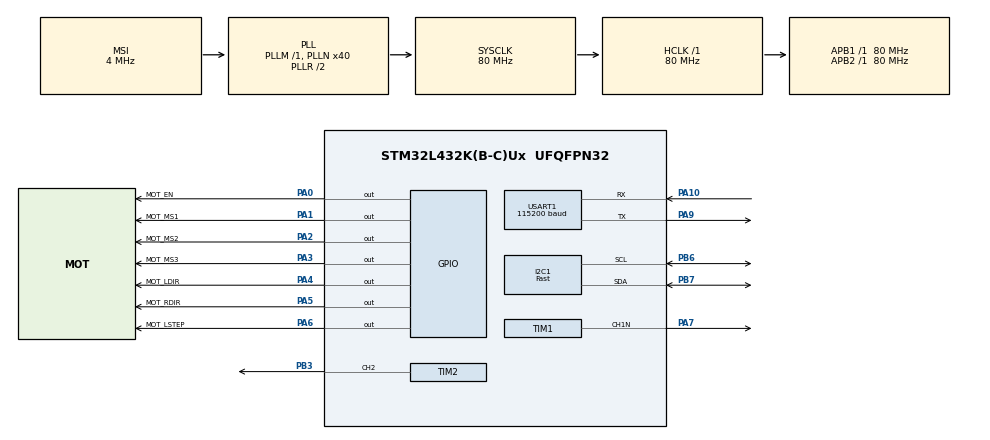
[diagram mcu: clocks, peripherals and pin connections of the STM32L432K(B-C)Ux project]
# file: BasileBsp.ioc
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I2C1.I2C_Speed_Mode=I2C_Fast
I2C1.Timing=0x00702991
Mcu.Family=STM32L4
Mcu.Name=STM32L432K(B-C)Ux
Mcu.Package=UFQFPN32
NVIC.PriorityGroup=NVIC_PRIORITYGROUP_4
NVIC.TIM1_UP_TIM16_IRQn=true\:0\:0\:false\:false\:true\:true
PA0.GPIO_Label=MOT_EN
PA0.GPIO_Speed=GPIO_SPEED_FREQ_VERY_HIGH
PA0.PinState=GPIO_PIN_SET
PA0.Signal=GPIO_Output
PA1.GPIO_Label=MOT_MS1
PA1.GPIO_ModeDefaultOutputPP=GPIO_MODE_OUTPUT_PP
PA1.GPIO_Speed=GPIO_SPEED_FREQ_VERY_HIGH
PA1.PinState=GPIO_PIN_RESET
PA1.Signal=GPIO_Output
PA10.Mode=Asynchronous
PA10.Signal=USART1_RX
PA13\ (JTMS-SWDIO).Mode=Serial_Wire
PA13\ (JTMS-SWDIO).Signal=SYS_JTMS-SWDIO
PA14\ (JTCK-SWCLK).Mode=Serial_Wire
PA14\ (JTCK-SWCLK).Signal=SYS_JTCK-SWCLK
PA2.GPIO_Label=MOT_MS2
PA2.GPIO_ModeDefaultOutputPP=GPIO_MODE_OUTPUT_PP
PA2.GPIO_Speed=GPIO_SPEED_FREQ_VERY_HIGH
PA2.PinState=GPIO_PIN_RESET
PA2.Signal=GPIO_Output
PA3.GPIO_Label=MOT_MS3
PA3.GPIO_ModeDefaultOutputPP=GPIO_MODE_OUTPUT_PP
PA3.GPIO_Speed=GPIO_SPEED_FREQ_VERY_HIGH
PA3.PinState=GPIO_PIN_RESET
PA3.Signal=GPIO_Output
PA4.GPIO_Label=MOT_LDIR
PA4.GPIO_Speed=GPIO_SPEED_FREQ_VERY_HIGH
PA4.Signal=GPIO_Output
PA5.GPIO_Label=MOT_RDIR
PA5.GPIO_Speed=GPIO_SPEED_FREQ_VERY_HIGH
PA5.Signal=GPIO_Output
PA6.GPIO_Label=MOT_LSTEP
PA6.GPIO_Speed=GPIO_SPEED_FREQ_VERY_HIGH
PA6.Signal=GPIO_Output
PA7.Mode=PWM Generation1 CH1N
PA7.Signal=TIM1_CH1N
PA9.Mode=Asynchronous
PA9.Signal=USART1_TX
PB3\ (JTDO-TRACESWO).GPIO_Speed=GPIO_SPEED_FREQ_VERY_HIGH
PB3\ (JTDO-TRACESWO).Signal=S_TIM2_CH2
PB6.Mode=I2C
PB6.Signal=I2C1_SCL
PB7.Mode=I2C
PB7.Signal=I2C1_SDA
ProjectManager.HeapSize=0x200
ProjectManager.StackSize=0x400
ProjectManager.TargetToolchain=Makefile
RCC.AHBFreq_Value=80000000
RCC.APB1Freq_Value=80000000
RCC.APB1TimFreq_Value=80000000
RCC.APB2Freq_Value=80000000
RCC.APB2TimFreq_Value=80000000
RCC.CortexFreq_Value=80000000
RCC.HCLKFreq_Value=80000000
RCC.HSE_VALUE=8000000
RCC.HSI48_VALUE=48000000
RCC.HSI_VALUE=16000000
RCC.LSE_VALUE=32768
RCC.MSI_VALUE=4000000
RCC.PLLN=40
RCC.SYSCLKFreq_VALUE=80000000
RCC.SYSCLKSource=RCC_SYSCLKSOURCE_PLLCLK
RCC.VCOOutputFreq_Value=160000000
SH.S_TIM2_CH2.0=TIM2_CH2,PWM Generation2 CH2
TIM1.AutoReloadPreload=TIM_AUTORELOAD_PRELOAD_ENABLE
TIM1.Channel-PWM\ Generation1\ CH1N=TIM_CHANNEL_1
TIM1.Period=2000
TIM1.Prescaler=80
TIM1.Pulse-PWM\ Generation1\ CH1N=1000
TIM2.AutoReloadPreload=TIM_AUTORELOAD_PRELOAD_ENABLE
TIM2.Channel-PWM\ Generation2\ CH2=TIM_CHANNEL_2
TIM2.ClockDivision=TIM_CLOCKDIVISION_DIV1
TIM2.Period=2000
TIM2.Prescaler=40000
TIM2.Pulse-PWM\ Generation2\ CH2=100
USART1.BaudRate=115200
USART1.VirtualMode-Asynchronous=VM_ASYNC
USART1.WordLength=WORDLENGTH_8B
VP_TIM1_VS_ClockSourceINT.Mode=Internal
VP_TIM2_VS_ClockSourceINT.Mode=Internal
board=BasileBsp

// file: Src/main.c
/**
  ******************************************************************************
  * File Name          : main.c
  * Description        : Main program body
  ******************************************************************************
  ** This notice applies to any and all portions of this file
  * that are not between comment pairs USER CODE BEGIN and
  * USER CODE END. Other portions of this file, whether
  * inserted by the user or by software development tools
  * are owned by their respective copyright owners.
  *
  * COPYRIGHT(c) 2017 STMicroelectronics
  *
  * Redistribution and use in source and binary forms, with or without modification,
  * are permitted provided that the following conditions are met:
  *   1. Redistributions of source code must retain the above copyright notice,
  *      this list of conditions and the following disclaimer.
  *   2. Redistributions in binary form must reproduce the above copyright notice,
  *      this list of conditions and the following disclaimer in the documentation
  *      and/or other materials provided with the distribution.
  *   3. Neither the name of STMicroelectronics nor the names of its contributors
  *      may be used to endorse or promote products derived from this software
  *      without specific prior written permission.
  *
  * THIS SOFTWARE IS PROVIDED BY THE COPYRIGHT HOLDERS AND CONTRIBUTORS "AS IS"
  * AND ANY EXPRESS OR IMPLIED WARRANTIES, INCLUDING, BUT NOT LIMITED TO, THE
  * IMPLIED WARRANTIES OF MERCHANTABILITY AND FITNESS FOR A PARTICULAR PURPOSE ARE
  * DISCLAIMED. IN NO EVENT SHALL THE COPYRIGHT HOLDER OR CONTRIBUTORS BE LIABLE
  * FOR ANY DIRECT, INDIRECT, INCIDENTAL, SPECIAL, EXEMPLARY, OR CONSEQUENTIAL
  * DAMAGES (INCLUDING, BUT NOT LIMITED TO, PROCUREMENT OF SUBSTITUTE GOODS OR
  * SERVICES; LOSS OF USE, DATA, OR PROFITS; OR BUSINESS INTERRUPTION) HOWEVER
  * CAUSED AND ON ANY THEORY OF LIABILITY, WHETHER IN CONTRACT, STRICT LIABILITY,
  * OR TORT (INCLUDING NEGLIGENCE OR OTHERWISE) ARISING IN ANY WAY OUT OF THE USE
  * OF THIS SOFTWARE, EVEN IF ADVISED OF THE POSSIBILITY OF SUCH DAMAGE.
  *
  ******************************************************************************
  */

#include "main.h"
#include "stm32l4xx_hal.h"

/* USER CODE BEGIN Includes */

#include "CommChannel.h"
#include "HC06Configurator.h"
#include "Time.h"
#include "Imu.h"
#include "MotorDriver.h"
#include "Log.h"

/* USER CODE END Includes */

I2C_HandleTypeDef hi2c1;

TIM_HandleTypeDef htim1;
TIM_HandleTypeDef htim2;

UART_HandleTypeDef huart1;

/* USER CODE BEGIN PV */
/* Private variables ---------------------------------------------------------*/

/* USER CODE END PV */

void SystemClock_Config(void);
static void MX_GPIO_Init(void);
static void MX_USART1_UART_Init(void);
static void MX_I2C1_Init(void);
static void MX_TIM1_Init(void);
static void MX_TIM2_Init(void);

void HAL_TIM_MspPostInit(TIM_HandleTypeDef *htim);

/* USER CODE BEGIN PFP */
/* Private function prototypes -----------------------------------------------*/

/* USER CODE END PFP */

int main(void)
{

  /* MCU Configuration----------------------------------------------------------*/

  /* Reset of all peripherals, Initializes the Flash interface and the Systick. */
  HAL_Init();

  /* Configure the system clock */
  SystemClock_Config();

  /* Initialize all configured peripherals */
  MX_GPIO_Init();
  MX_USART1_UART_Init();
  MX_I2C1_Init();
  MX_TIM1_Init();
  MX_TIM2_Init();

  /* USER CODE BEGIN 2 */
   CommChannel_Initialize();
   CommChannel_Write("AT\r\n", 4);
   //Imu_Initialize();
   //Motor_Initialize();

   HAL_TIM_Base_Start(&htim2);
   HAL_TIM_OC_Start(&htim2, TIM_CHANNEL_2);
  /* USER CODE END 2 */

  /* Infinite loop */
  /* USER CODE BEGIN WHILE */

   float minspeed = 0.5f, maxspeed = 10.0f, acc = 10.0f;
   int dir = 1;
   //Motor_Enable();
   //Motor_SetAcceleration(acc);

   while (1)
   {
  /* USER CODE END WHILE */

  /* USER CODE BEGIN 3 */

      Log_Info("Pomme");
      /*
      if (dir > 0 && Motor_GetSpeed() > maxspeed)
      {
         dir = -1;
         Motor_SetAcceleration(-acc);
      }
      else if (dir < 0 && Motor_GetSpeed() < minspeed)
      {
         dir = 1;
         Motor_SetAcceleration(acc);
      }

      //GPIOA->ODR ^= 1 << 7;
      Time_Wait(1);
      Motor_Process(1e-3f);*/
   }
  /* USER CODE END 3 */

}

/** System Clock Configuration
*/
void SystemClock_Config(void)
{

  RCC_OscInitTypeDef RCC_OscInitStruct;
  RCC_ClkInitTypeDef RCC_ClkInitStruct;
  RCC_PeriphCLKInitTypeDef PeriphClkInit;

    /**Initializes the CPU, AHB and APB busses clocks
    */
  RCC_OscInitStruct.OscillatorType = RCC_OSCILLATORTYPE_MSI;
  RCC_OscInitStruct.MSIState = RCC_MSI_ON;
  RCC_OscInitStruct.MSICalibrationValue = 0;
  RCC_OscInitStruct.MSIClockRange = RCC_MSIRANGE_6;
  RCC_OscInitStruct.PLL.PLLState = RCC_PLL_ON;
  RCC_OscInitStruct.PLL.PLLSource = RCC_PLLSOURCE_MSI;
  RCC_OscInitStruct.PLL.PLLM = 1;
  RCC_OscInitStruct.PLL.PLLN = 40;
  RCC_OscInitStruct.PLL.PLLP = RCC_PLLP_DIV7;
  RCC_OscInitStruct.PLL.PLLQ = RCC_PLLQ_DIV2;
  RCC_OscInitStruct.PLL.PLLR = RCC_PLLR_DIV2;
  if (HAL_RCC_OscConfig(&RCC_OscInitStruct) != HAL_OK)
  {
    _Error_Handler(__FILE__, __LINE__);
  }

    /**Initializes the CPU, AHB and APB busses clocks
    */
  RCC_ClkInitStruct.ClockType = RCC_CLOCKTYPE_HCLK|RCC_CLOCKTYPE_SYSCLK
                              |RCC_CLOCKTYPE_PCLK1|RCC_CLOCKTYPE_PCLK2;
  RCC_ClkInitStruct.SYSCLKSource = RCC_SYSCLKSOURCE_PLLCLK;
  RCC_ClkInitStruct.AHBCLKDivider = RCC_SYSCLK_DIV1;
  RCC_ClkInitStruct.APB1CLKDivider = RCC_HCLK_DIV1;
  RCC_ClkInitStruct.APB2CLKDivider = RCC_HCLK_DIV1;

  if (HAL_RCC_ClockConfig(&RCC_ClkInitStruct, FLASH_LATENCY_4) != HAL_OK)
  {
    _Error_Handler(__FILE__, __LINE__);
  }

  PeriphClkInit.PeriphClockSelection = RCC_PERIPHCLK_USART1|RCC_PERIPHCLK_I2C1;
  PeriphClkInit.Usart1ClockSelection = RCC_USART1CLKSOURCE_PCLK2;
  PeriphClkInit.I2c1ClockSelection = RCC_I2C1CLKSOURCE_PCLK1;
  if (HAL_RCCEx_PeriphCLKConfig(&PeriphClkInit) != HAL_OK)
  {
    _Error_Handler(__FILE__, __LINE__);
  }

    /**Configure the main internal regulator output voltage
    */
  if (HAL_PWREx_ControlVoltageScaling(PWR_REGULATOR_VOLTAGE_SCALE1) != HAL_OK)
  {
    _Error_Handler(__FILE__, __LINE__);
  }

    /**Configure the Systick interrupt time
    */
  HAL_SYSTICK_Config(HAL_RCC_GetHCLKFreq()/1000);

    /**Configure the Systick
    */
  HAL_SYSTICK_CLKSourceConfig(SYSTICK_CLKSOURCE_HCLK);

  /* SysTick_IRQn interrupt configuration */
  HAL_NVIC_SetPriority(SysTick_IRQn, 0, 0);
}

/* I2C1 init function */
static void MX_I2C1_Init(void)
{

  hi2c1.Instance = I2C1;
  hi2c1.Init.Timing = 0x00702991;
  hi2c1.Init.OwnAddress1 = 0;
  hi2c1.Init.AddressingMode = I2C_ADDRESSINGMODE_7BIT;
  hi2c1.Init.DualAddressMode = I2C_DUALADDRESS_DISABLE;
  hi2c1.Init.OwnAddress2 = 0;
  hi2c1.Init.OwnAddress2Masks = I2C_OA2_NOMASK;
  hi2c1.Init.GeneralCallMode = I2C_GENERALCALL_DISABLE;
  hi2c1.Init.NoStretchMode = I2C_NOSTRETCH_DISABLE;
  if (HAL_I2C_Init(&hi2c1) != HAL_OK)
  {
    _Error_Handler(__FILE__, __LINE__);
  }

    /**Configure Analogue filter
    */
  if (HAL_I2CEx_ConfigAnalogFilter(&hi2c1, I2C_ANALOGFILTER_ENABLE) != HAL_OK)
  {
    _Error_Handler(__FILE__, __LINE__);
  }

    /**Configure Digital filter
    */
  if (HAL_I2CEx_ConfigDigitalFilter(&hi2c1, 0) != HAL_OK)
  {
    _Error_Handler(__FILE__, __LINE__);
  }

}

/* TIM1 init function */
static void MX_TIM1_Init(void)
{

  TIM_ClockConfigTypeDef sClockSourceConfig;
  TIM_MasterConfigTypeDef sMasterConfig;
  TIM_OC_InitTypeDef sConfigOC;
  TIM_BreakDeadTimeConfigTypeDef sBreakDeadTimeConfig;

  htim1.Instance = TIM1;
  htim1.Init.Prescaler = 80;
  htim1.Init.CounterMode = TIM_COUNTERMODE_UP;
  htim1.Init.Period = 2000;
  htim1.Init.ClockDivision = TIM_CLOCKDIVISION_DIV1;
  htim1.Init.RepetitionCounter = 0;
  htim1.Init.AutoReloadPreload = TIM_AUTORELOAD_PRELOAD_ENABLE;
  if (HAL_TIM_Base_Init(&htim1) != HAL_OK)
  {
    _Error_Handler(__FILE__, __LINE__);
  }

  sClockSourceConfig.ClockSource = TIM_CLOCKSOURCE_INTERNAL;
  if (HAL_TIM_ConfigClockSource(&htim1, &sClockSourceConfig) != HAL_OK)
  {
    _Error_Handler(__FILE__, __LINE__);
  }

  if (HAL_TIM_PWM_Init(&htim1) != HAL_OK)
  {
    _Error_Handler(__FILE__, __LINE__);
  }

  sMasterConfig.MasterOutputTrigger = TIM_TRGO_RESET;
  sMasterConfig.MasterOutputTrigger2 = TIM_TRGO2_RESET;
  sMasterConfig.MasterSlaveMode = TIM_MASTERSLAVEMODE_DISABLE;
  if (HAL_TIMEx_MasterConfigSynchronization(&htim1, &sMasterConfig) != HAL_OK)
  {
    _Error_Handler(__FILE__, __LINE__);
  }

  sConfigOC.OCMode = TIM_OCMODE_PWM1;
  sConfigOC.Pulse = 1000;
  sConfigOC.OCPolarity = TIM_OCPOLARITY_HIGH;
  sConfigOC.OCNPolarity = TIM_OCNPOLARITY_HIGH;
  sConfigOC.OCFastMode = TIM_OCFAST_DISABLE;
  sConfigOC.OCIdleState = TIM_OCIDLESTATE_RESET;
  sConfigOC.OCNIdleState = TIM_OCNIDLESTATE_RESET;
  if (HAL_TIM_PWM_ConfigChannel(&htim1, &sConfigOC, TIM_CHANNEL_1) != HAL_OK)
  {
    _Error_Handler(__FILE__, __LINE__);
  }

  sBreakDeadTimeConfig.OffStateRunMode = TIM_OSSR_DISABLE;
  sBreakDeadTimeConfig.OffStateIDLEMode = TIM_OSSI_DISABLE;
  sBreakDeadTimeConfig.LockLevel = TIM_LOCKLEVEL_OFF;
  sBreakDeadTimeConfig.DeadTime = 0;
  sBreakDeadTimeConfig.BreakState = TIM_BREAK_DISABLE;
  sBreakDeadTimeConfig.BreakPolarity = TIM_BREAKPOLARITY_HIGH;
  sBreakDeadTimeConfig.BreakFilter = 0;
  sBreakDeadTimeConfig.Break2State = TIM_BREAK2_DISABLE;
  sBreakDeadTimeConfig.Break2Polarity = TIM_BREAK2POLARITY_HIGH;
  sBreakDeadTimeConfig.Break2Filter = 0;
  sBreakDeadTimeConfig.AutomaticOutput = TIM_AUTOMATICOUTPUT_DISABLE;
  if (HAL_TIMEx_ConfigBreakDeadTime(&htim1, &sBreakDeadTimeConfig) != HAL_OK)
  {
    _Error_Handler(__FILE__, __LINE__);
  }

  HAL_TIM_MspPostInit(&htim1);

}

/* TIM2 init function */
static void MX_TIM2_Init(void)
{

  TIM_ClockConfigTypeDef sClockSourceConfig;
  TIM_MasterConfigTypeDef sMasterConfig;
  TIM_OC_InitTypeDef sConfigOC;

  htim2.Instance = TIM2;
  htim2.Init.Prescaler = 40000;
  htim2.Init.CounterMode = TIM_COUNTERMODE_UP;
  htim2.Init.Period = 2000;
  htim2.Init.ClockDivision = TIM_CLOCKDIVISION_DIV1;
  htim2.Init.AutoReloadPreload = TIM_AUTORELOAD_PRELOAD_ENABLE;
  if (HAL_TIM_Base_Init(&htim2) != HAL_OK)
  {
    _Error_Handler(__FILE__, __LINE__);
  }

  sClockSourceConfig.ClockSource = TIM_CLOCKSOURCE_INTERNAL;
  if (HAL_TIM_ConfigClockSource(&htim2, &sClockSourceConfig) != HAL_OK)
  {
    _Error_Handler(__FILE__, __LINE__);
  }

  if (HAL_TIM_PWM_Init(&htim2) != HAL_OK)
  {
    _Error_Handler(__FILE__, __LINE__);
  }

  sMasterConfig.MasterOutputTrigger = TIM_TRGO_RESET;
  sMasterConfig.MasterSlaveMode = TIM_MASTERSLAVEMODE_DISABLE;
  if (HAL_TIMEx_MasterConfigSynchronization(&htim2, &sMasterConfig) != HAL_OK)
  {
    _Error_Handler(__FILE__, __LINE__);
  }

  sConfigOC.OCMode = TIM_OCMODE_PWM1;
  sConfigOC.Pulse = 100;
  sConfigOC.OCPolarity = TIM_OCPOLARITY_HIGH;
  sConfigOC.OCFastMode = TIM_OCFAST_DISABLE;
  if (HAL_TIM_PWM_ConfigChannel(&htim2, &sConfigOC, TIM_CHANNEL_2) != HAL_OK)
  {
    _Error_Handler(__FILE__, __LINE__);
  }

  HAL_TIM_MspPostInit(&htim2);

}

/* USART1 init function */
static void MX_USART1_UART_Init(void)
{

  huart1.Instance = USART1;
  huart1.Init.BaudRate = 115200;
  huart1.Init.WordLength = UART_WORDLENGTH_8B;
  huart1.Init.StopBits = UART_STOPBITS_1;
  huart1.Init.Parity = UART_PARITY_NONE;
  huart1.Init.Mode = UART_MODE_TX_RX;
  huart1.Init.HwFlowCtl = UART_HWCONTROL_NONE;
  huart1.Init.OverSampling = UART_OVERSAMPLING_16;
  huart1.Init.OneBitSampling = UART_ONE_BIT_SAMPLE_DISABLE;
  huart1.AdvancedInit.AdvFeatureInit = UART_ADVFEATURE_NO_INIT;
  if (HAL_UART_Init(&huart1) != HAL_OK)
  {
    _Error_Handler(__FILE__, __LINE__);
  }

}

/** Configure pins as
        * Analog
        * Input
        * Output
        * EVENT_OUT
        * EXTI
*/
static void MX_GPIO_Init(void)
{

  GPIO_InitTypeDef GPIO_InitStruct;

  /* GPIO Ports Clock Enable */
  __HAL_RCC_GPIOA_CLK_ENABLE();
  __HAL_RCC_GPIOB_CLK_ENABLE();

  /*Configure GPIO pin Output Level */
  HAL_GPIO_WritePin(MOT_EN_GPIO_Port, MOT_EN_Pin, GPIO_PIN_SET);

  /*Configure GPIO pin Output Level */
  HAL_GPIO_WritePin(GPIOA, MOT_MS1_Pin|MOT_MS2_Pin|MOT_MS3_Pin|MOT_LDIR_Pin
                          |MOT_RDIR_Pin|MOT_LSTEP_Pin, GPIO_PIN_RESET);

  /*Configure GPIO pins : MOT_EN_Pin MOT_MS1_Pin MOT_MS2_Pin MOT_MS3_Pin
                           MOT_LDIR_Pin MOT_RDIR_Pin MOT_LSTEP_Pin */
  GPIO_InitStruct.Pin = MOT_EN_Pin|MOT_MS1_Pin|MOT_MS2_Pin|MOT_MS3_Pin
                          |MOT_LDIR_Pin|MOT_RDIR_Pin|MOT_LSTEP_Pin;
  GPIO_InitStruct.Mode = GPIO_MODE_OUTPUT_PP;
  GPIO_InitStruct.Pull = GPIO_NOPULL;
  GPIO_InitStruct.Speed = GPIO_SPEED_FREQ_VERY_HIGH;
  HAL_GPIO_Init(GPIOA, &GPIO_InitStruct);

}

void _Error_Handler(char * file, int line)
{
   while (1)
   {
   }
}

/************************ (C) COPYRIGHT STMicroelectronics *****END OF FILE****/
